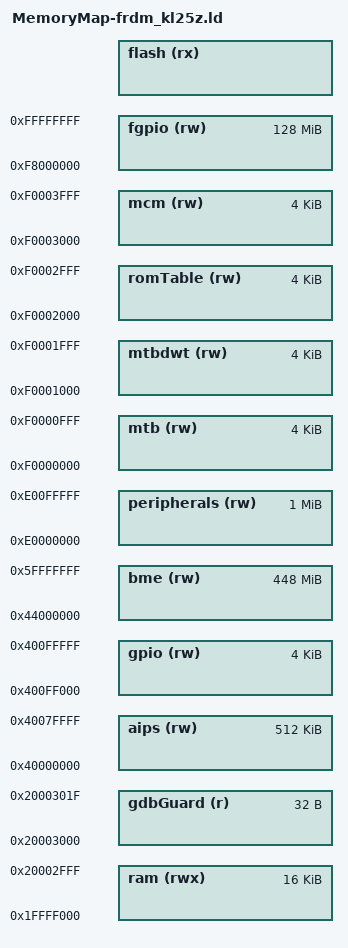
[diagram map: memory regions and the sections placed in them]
/* MemoryMap.ld (Packages\100.ARM_DeviceOptions\Project_Settings\Linker_Files)
 *
 * Memory map for devices without SRAM_U allocation for bit-band/bme
 */
 
/* ---- <<< Use Configuration Wizard in Context Menu >>> ---- */

/* <o> Stack Size
   <i> Required amount of stack space
   <i> In CMSIS this will determine the ISR stack size
   <0x0-0x4000:4> 
*/
__stack_size = 0x1000;

/* <o> Minimum Heap Size 
   <i> This is the minimum allocated.  
   <i> Available heap may be larger.
   <0x0-0x4000:4> 
*/
__heap_size  = 0x1000;
  
/*
 * Memory Map generated by USBDM New Project Wizard for FRDM_KL25Z
 
    <o>  Bootloader size <constant>
    <i>  The bootloader is located at the bottom of the flash region
    <i>  This value is used to automatically adjust the available flash area 
 */

BOOT_LOADER_SIZE  = DEFINED(BOOT_LOADER_SIZE)  ? BOOT_LOADER_SIZE : 0x0000;
 
MEMORY
{
  aips           (rw)  : ORIGIN = 0x40000000, LENGTH = 0x00080000
  gpio           (rw)  : ORIGIN = 0x400FF000, LENGTH = 0x00001000
  bme            (rw)  : ORIGIN = 0x44000000, LENGTH = 0x1C000000
  peripherals    (rw)  : ORIGIN = 0xE0000000, LENGTH = 0x00100000
  mtb            (rw)  : ORIGIN = 0xF0000000, LENGTH = 0x00001000
  mtbdwt         (rw)  : ORIGIN = 0xF0001000, LENGTH = 0x00001000
  romTable       (rw)  : ORIGIN = 0xF0002000, LENGTH = 0x00001000
  mcm            (rw)  : ORIGIN = 0xF0003000, LENGTH = 0x00001000
  fgpio          (rw)  : ORIGIN = 0xF8000000, LENGTH = 0x08000000
/*
    <o>  FLASH  address <constant>
    <o1> FLASH  size    <constant>
 */
  flash          (rx)  : ORIGIN = 0x00000000+BOOT_LOADER_SIZE, LENGTH = 0x00020000-BOOT_LOADER_SIZE
/*
    <o>  ram    address <constant>
    <o1> ram    size    <constant>
 */
  ram            (rwx) : ORIGIN = 0x1FFFF000, LENGTH = 0x00004000
/*
 * Guard region above stack for GDB 
 */
  gdbGuard       (r)   : ORIGIN = 0x20003000, LENGTH = 0x00000020
};





